# DMTimer register map
Vendor: Texas Instruments
Peripheral module from a debugger description file (folder am335x).
Registers are 32-bit, access per field, no defined reset value unless marked. A register's access mark holds for its fields unless they carry their own. Offsets are as the file gives them; lines under a group give offsets from that group; [hi:lo] are bit positions; {n}, {i} and the like mark numbered series; 'fields as' and 'values as' point back to an identical list; <NAME> marks a mode.

## TIMER
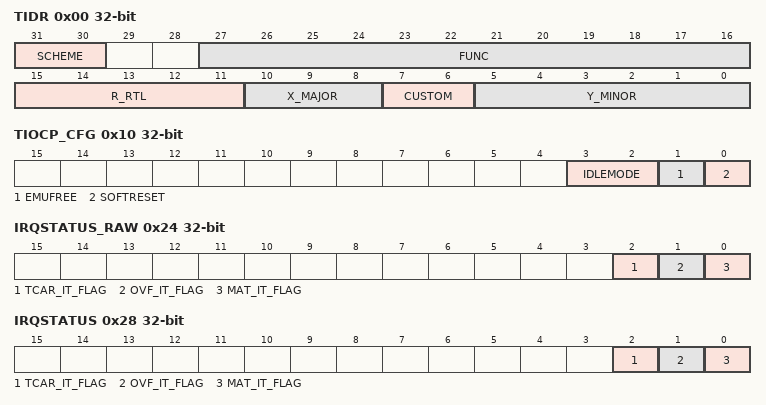
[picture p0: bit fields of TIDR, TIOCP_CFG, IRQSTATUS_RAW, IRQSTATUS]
0x00 TIDR — This read only register contains the revision number of the module. A write to this register has no effect. This register is used by software to track features, bugs, and compatibility.
  [31:30] SCHEME rw — Used to distinguish between old scheme and current.
  [27:16] FUNC rw — Function indicates a software compatible module family.
  [15:11] R_RTL rw — RTL Version (R).
  [10:8] X_MAJOR rw — Major Revision (X).
  [7:6] CUSTOM rw — Indicates a special version for a particular device.
  [5:0] Y_MINOR rw — Minor Revision (Y).
0x10 TIOCP_CFG — This register allows controlling various parameters of the OCP interface.
  [3:2] IDLEMODE rw — Power management, req/ack control
  [1] EMUFREE rw — Emulation mode
  [0] SOFTRESET rw — Software reset.
0x24 IRQSTATUS_RAW — Component interrupt request status. Check the corresponding secondary status register. Raw status is set even if event is not enabled. Write 1 to set the (raw) status, mostly for debug.
  [2] TCAR_IT_FLAG rw — IRQ status for Capture
  [1] OVF_IT_FLAG rw — IRQ status for Overflow
  [0] MAT_IT_FLAG rw — IRQ status for Match
0x28 IRQSTATUS — Component interrupt request status. Check the corresponding secondary status register. Enabled status is not set unless event is enabled. Write 1 to clear the status after interrupt has been serviced (raw status gets cleared, that is, even if not enabled).
  fields as IRQSTATUS_RAW
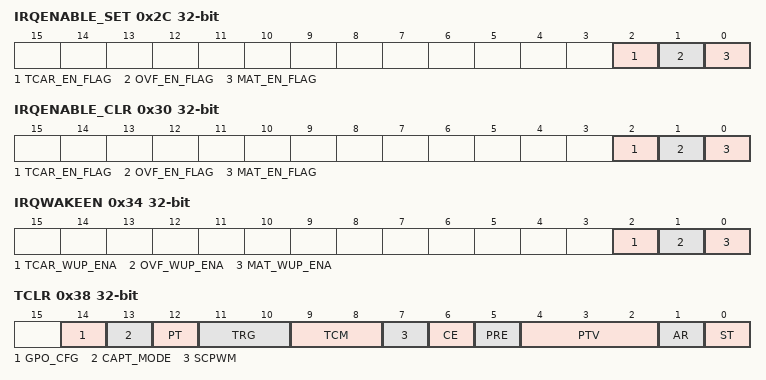
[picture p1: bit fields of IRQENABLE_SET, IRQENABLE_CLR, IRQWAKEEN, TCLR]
0x2C IRQENABLE_SET — Component interrupt request enable. Write 1 to set (enable interrupt). Readout equal to corresponding _CLR register.
  [2] TCAR_EN_FLAG rw — IRQ enable for Compare
  [1] OVF_EN_FLAG rw — IRQ enable for Overflow
  [0] MAT_EN_FLAG rw — IRQ enable for Match
0x30 IRQENABLE_CLR — Component interrupt request enable. Write 1 to clear (disable interrupt). Readout equal to corresponding _SET register.
  fields as IRQENABLE_SET
0x34 IRQWAKEEN — Wakeup-enabled events taking place when module is idle will generate an asynchronous wakeup.
  [2] TCAR_WUP_ENA rw — Wakeup generation for Compare
  [1] OVF_WUP_ENA rw — Wakeup generation for Overflow
  [0] MAT_WUP_ENA rw — Wakeup generation for Match
0x38 TCLR — When the TCM field passed from (00) to any other combination then the TCAR_IT_FLAG and the edge detection logic are cleared. The ST bit of TCLR register may be updated from the OCP interface or reset due to one-shot overflow. The OCP interface update has the priority.
  [14] GPO_CFG rw — General purpose output this register drives directly the PORGPOCFG output pin
  [13] CAPT_MODE rw — Capture mode.
  [12] PT rw — Pulse or toggle mode on PORTIMERPWM output pin
  [11:10] TRG rw — Trigger output mode on PORTIMERPWM output pin
  [9:8] TCM rw — Transition Capture Mode on PIEVENTCAPT input pin
  [7] SCPWM rw — This bit should be set or clear while the timer is stopped or the trigger is off
  [6] CE rw
  [5] PRE rw — Prescaler enable
  [4:2] PTV rw — Pre-scale clock Timer value
  [1] AR rw
  [0] ST rw — In the case of one-shot mode selected (AR = 0), this bit is automatically reset by internal logic when the counter is overflowed.
0x3C TCRR rw — The TCRR register is a 32-bit register, 16-bit addressable. The MCU can perform a 32-bit access or two 16-bit accesses to access the register . Note that since the OCP clock is completely asynchronous with the timer clock, some synchronization is done in order to make sure that the TCRR value is not read while it is being incremented. In 16-bit mode the following sequence must be followed to read the TCRR register properly: First, perform an OCP Read Transaction to Read the lower 16-bit of the TCRR register (offset = 28h). When the TCRR is read and synchronized, the lower 16-bit LSBs are driven onto the output OCP data bus and the upper 16-bit MSBs of the TCRR register are stored in a temporary register. Second, perform an OCP Read Transaction to read the upper 16-bit of the TCRR register (offset = 2Ah). During this Read, the value of the upper 16-bit MSBs that has been temporary register is forwarded onto the output OCP data bus. So, to read the value of TCRR correctly, the first OCP read access has to be to the lower 16-bit (offset = 28h), followed by OCP read access to the upper 16-bit (offset = 2Ah). As the TCRR is updated using more sources (shadow_in_tcrr, incremented value of tcrr, TLDR and 0 ), a priority order will be defined: The first priority is the OCP update. The second is the reload way (triggered through TTGR reg. or following an auto-reload overflow). The third is the one-shot overflow reset to 0. The last is the incremented value.
  [31:0] TIMER_COUNTER — Value of TIMER counter
0x40 TLDR rw — LOAD_VALUE must be different than the timer overflow value (FFFF FFFFh).
  [31:0] LOAD_VALUE — Timer counter value loaded on overflow in auto-reload mode or on TTGR write access
0x44 TTGR rw — The read value of this register is always FFFF FFFFh.
  [31:0] TTGR_VALUE — Writing in the TTGR register, TCRR will be loaded from TLDR and prescaler counter will be cleared. Reload will be done regardless of the AR field value of TCLR register.
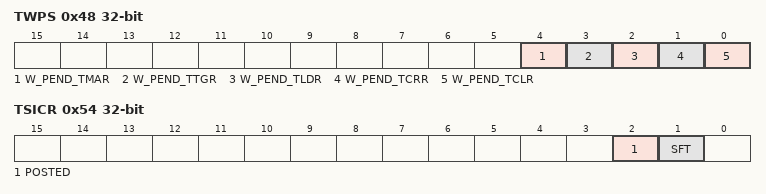
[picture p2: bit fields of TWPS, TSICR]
0x48 TWPS — In posted mode the software must read the pending write status bits (Timer Write Posted Status register bits [4:0]) to insure that following write access will not be discarded due to on going write synchronization process. These bits are automatically cleared by internal logic when the write to the corresponding register is acknowledged.
  [4] W_PEND_TMAR rw — When equal to 1, a write is pending to the TMAR register
  [3] W_PEND_TTGR rw — When equal to 1, a write is pending to the TTGR register
  [2] W_PEND_TLDR rw — When equal to 1, a write is pending to the TLDR register
  [1] W_PEND_TCRR rw — When equal to 1, a write is pending to the TCRR register
  [0] W_PEND_TCLR rw — When equal to 1, a write is pending to the TCLR register
0x4C TMAR rw — The compare logic consists of a 32-bit wide, read/write data TMAR register and logic to compare counter s current value with the value stored in the TMAR register.
  [31:0] COMPARE_VALUE — Value to be compared to the timer counter
0x50 TCAR1 rw — When the appropriate (rising, falling or both) transition is detected in the edge detection logic the current counter value is stored to the TCAR1 register. Note that since the OCP clock is completely asynchronous with the timer clock, some synchronization is done in order to make sure that the TCAR1 value is not read while it is being updated due to some capture event. In 16-bit mode the following sequence must be followed to read the TCAR1 register properly:
  [31:0] CAPTURED_VALUE — Timer counter value captured on an external event trigger
0x54 TSICR — Access to this register is not stalled even if the timer is in non-posted mode configuration. To abort any wrong behavior, software can permanently reset the functional part of the module. Also in case of a wrong hardware PIFREQRATIO tied the POSTED field can be reprogrammed on the fly, so deadlock situation cannot happen. Reset value of POSTED depends on hardware integration module at design time. Software must read POSTED field to get the hardware module configuration.
  [2] POSTED rw — PIFREQRATIO
  [1] SFT rw — This bit resets all the function parts of the module. During reads it always returns 0.
0x58 TCAR2 rw — When the appropriate (rising, falling or both) transition is detected in the edge detection logic and the capture on second event is activated from the control register (TCLR), the current counter value is stored to the TCAR2 register. Note that since the OCP clock is completely asynchronous with the timer clock, some synchronization is done in order to make sure that the TCAR2 value is not read while it is being updated due to some capture event. In 16-bit mode the following sequence must be followed to read the TCAR2 register properly: First, perform an OCP Read Transaction to Read the lower 16-bits of the TCAR2 register. Second, perform an OCP Read Transaction to read the upper 16-bits of the TCAR2 register.
  fields as TCAR1
